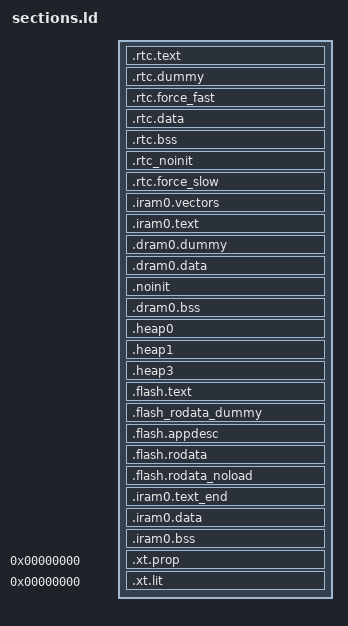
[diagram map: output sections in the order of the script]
/*
 * ESP32-S3 Linker Script Output Sections
 *
 * This Source Code Form is subject to the terms of the Mozilla Public License, v. 2.0.
 * If a copy of the MPL was not distributed with this file, you can obtain one at
 * https://mozilla.org/MPL/2.0/.
 *
 * Copyright 2026, Roku, Inc.  All rights reserved.
 */

/* This file places compiler output into the memory blocks that memory.ld
   describes.  It follows the esp32 script beside it closely; the differences all
   come from two properties of the part, plus one property of LT.

   The D/IRAM overlap.  SRAM1 answers on both buses, so a byte spent on
   .iram0.text is a byte no longer available to .dram0.data.  .dram0.dummy below
   is what keeps the two from being handed out twice: it is a NOLOAD section at
   the head of dram_app0_seg that grows to exactly cover whatever IRAM was used.
   The esp32 needs nothing of the kind.

   Static data and heap0 share a segment.  On the esp32 the ROM and BT carve-outs
   force .data and .bss into dram_app1_seg with heap0 stranded in a separate hole
   below them.  Here there is no hole: .data, .noinit and .bss go at the bottom of
   dram_app0_seg and heap0 takes whatever is left above them, which is the natural
   arrangement and the one IDF uses.

   Archive placement rules name only archives LT actually links.  The esp32
   script was generated by IDF's build system and carries placement rules for
   forty-odd IDF component archives - libfreertos.a, libhal.a, libheap.a and so
   on - that an LT link never sees; they match nothing and are harmless, but
   there is no reason to reproduce them here.  What LT does link is its own
   libraries plus the prebuilt Espressif blobs listed in
   Esp32_MasterFirmwareImage.mk, and those are the ones named below.  Note that
   the esp32s3 set differs from the esp32 set: there is no librtc.a, because
   esp32s3 RTC support lives in ROM, and there is a libbtbb.a, which on the esp32
   is in ROM.
*/

/* Start of SRAM1 on the instruction bus.  .dram0.dummy needs this to work out
   how much of the D/IRAM overlap the IRAM sections consumed. */
_diram_i_start = 0x40378000;

/*  Default entry point:  */
ENTRY(call_start_cpu0);

SECTIONS
{
  /* RTC fast memory holds RTC wake stub code,
     including from any source file named rtc_wake_stub*.c
  */
  .rtc.text :
  {
    . = ALIGN(4);

    *(.rtc.literal .rtc.text .rtc.text.*)

    *rtc_wake_stub*.*(.literal .text .literal.* .text.*)
    _rtc_text_end = ABSOLUTE(.);
  } > rtc_iram_seg

  /*
    This section is required to skip rtc.text area because rtc_iram_seg and
    rtc_data_seg are reflect the same address space on different buses.
  */
  .rtc.dummy :
  {
    _rtc_dummy_start = ABSOLUTE(.);
    _rtc_fast_start = ABSOLUTE(.);
    . = SIZEOF(.rtc.text);
    _rtc_dummy_end = ABSOLUTE(.);
  } > rtc_data_seg

  /* This section located in RTC FAST Memory area.
     It holds data marked with RTC_FAST_ATTR attribute.
     See the file "esp_attr.h" for more information.
  */
  .rtc.force_fast :
  {
    . = ALIGN(4);
    _rtc_force_fast_start = ABSOLUTE(.);

    _coredump_rtc_fast_start = ABSOLUTE(.);
    *(.rtc.fast.coredump .rtc.fast.coredump.*)
    _coredump_rtc_fast_end = ABSOLUTE(.);

    *(.rtc.force_fast .rtc.force_fast.*)
    . = ALIGN(4) ;

    _rtc_force_fast_end = ABSOLUTE(.);
  } > rtc_data_seg

  /* RTC data section holds RTC wake stub
     data/rodata, including from any source file
     named rtc_wake_stub*.c and the data marked with
     RTC_DATA_ATTR, RTC_RODATA_ATTR attributes.
  */
  .rtc.data :
  {
    _rtc_data_start = ABSOLUTE(.);

    _coredump_rtc_start = ABSOLUTE(.);
    *(.rtc.coredump .rtc.coredump.*)
    _coredump_rtc_end = ABSOLUTE(.);
    *(.rtc.data .rtc.data.*)
    *(.rtc.rodata .rtc.rodata.*)

    *rtc_wake_stub*.*(.data .rodata .data.* .rodata.* .bss .bss.*)
    _rtc_data_end = ABSOLUTE(.);

  } > rtc_data_location

  /* RTC bss, from any source file named rtc_wake_stub*.c */
  .rtc.bss (NOLOAD) :
  {
    _rtc_bss_start = ABSOLUTE(.);
    *rtc_wake_stub*.*(.bss .bss.*)
    *rtc_wake_stub*.*(COMMON)

    *(.rtc.bss)

    _rtc_bss_end = ABSOLUTE(.);
  } > rtc_data_location

  /* This section holds data that should not be initialized at power up
     and will be retained during deep sleep.
     User data marked with RTC_NOINIT_ATTR will be placed
     into this section. See the file "esp_attr.h" for more information.
  */
  .rtc_noinit (NOLOAD):
  {
    . = ALIGN(4);
    _rtc_noinit_start = ABSOLUTE(.);
    *(.rtc_noinit .rtc_noinit.*)
    . = ALIGN(4) ;
    _rtc_noinit_end = ABSOLUTE(.);
  } > rtc_data_location

  /* This section located in RTC SLOW Memory area.
     It holds data marked with RTC_SLOW_ATTR attribute.
     See the file "esp_attr.h" for more information.
  */
  .rtc.force_slow :
  {
    . = ALIGN(4);
    _rtc_force_slow_start = ABSOLUTE(.);
    *(.rtc.force_slow .rtc.force_slow.*)
    . = ALIGN(4) ;
    _rtc_force_slow_end = ABSOLUTE(.);
  } > rtc_slow_seg

  /* Get size of rtc slow data based on rtc_data_location alias */
  _rtc_slow_length = (ORIGIN(rtc_slow_seg) == ORIGIN(rtc_data_location))
                        ? (_rtc_force_slow_end - _rtc_data_start)
                        : (_rtc_force_slow_end - _rtc_force_slow_start);

  _rtc_fast_length = (ORIGIN(rtc_slow_seg) == ORIGIN(rtc_data_location))
                        ? (_rtc_force_fast_end - _rtc_fast_start)
                        : (_rtc_noinit_end - _rtc_fast_start);

  ASSERT((_rtc_slow_length <= LENGTH(rtc_slow_seg)),
          "RTC_SLOW segment data does not fit.")

  ASSERT((_rtc_fast_length <= LENGTH(rtc_data_seg)),
          "RTC_FAST segment data does not fit.")

  /* Send .iram0 code to iram */
  .iram0.vectors :
  {
    _iram_start = ABSOLUTE(.);
    /* Vectors go to IRAM */
    _vector_table = ABSOLUTE(.);
    . = 0x0;
    KEEP(*(.WindowVectors.text));
    . = 0x180;
    KEEP(*(.Level2InterruptVector.text));
    . = 0x1c0;
    KEEP(*(.Level3InterruptVector.text));
    . = 0x200;
    KEEP(*(.Level4InterruptVector.text));
    . = 0x240;
    KEEP(*(.Level5InterruptVector.text));
    . = 0x280;
    KEEP(*(.DebugExceptionVector.text));
    . = 0x2c0;
    KEEP(*(.NMIExceptionVector.text));
    . = 0x300;
    KEEP(*(.KernelExceptionVector.text));
    . = 0x340;
    KEEP(*(.UserExceptionVector.text));
    . = 0x3C0;
    KEEP(*(.DoubleExceptionVector.text));
    . = 0x400;
    _invalid_pc_placeholder = ABSOLUTE(.);
    *(.*Vector.literal)

    *(.UserEnter.literal);
    *(.UserEnter.text);
    . = ALIGN (16);
    *(.entry.text)
    *(.init.literal)
    *(.init)

    _init_end = ABSOLUTE(.);
  } > iram0_0_seg

  .iram0.text :
  {
    /* Code marked as running out of IRAM */
    _iram_text_start = ABSOLUTE(.);

    /* The .iram1 catch-all is what places IRAM-resident code out of the
       prebuilt blobs, libbtbb.a among them. */
    *(.iram1 .iram1.*)

    *libnet80211.a:(.wifi0iram .wifi0iram.*)
    *libnet80211.a:(.wifirxiram .wifirxiram.*)
    *libnet80211.a:(.wifislprxiram .wifislprxiram.*)
    *libpp.a:(.wifi0iram .wifi0iram.*)
    *libpp.a:(.wifiorslpiram .wifiorslpiram.*)
    *libpp.a:(.wifirxiram .wifirxiram.*)
    *libpp.a:(.wifislprxiram .wifislprxiram.*)
    *libgcc.a:lib2funcs.*(.literal .literal.* .text .text.*)

  } > iram0_0_seg

  /**
   * This section keeps the IRAM sections above from being handed out a second
   * time as DRAM.  SRAM1 is one block of memory seen on two buses, so whatever
   * .iram0.* consumed between _diram_i_start and _iram_end has to be skipped
   * here before any data section is placed.  MAX(...,0) covers the case where
   * nothing landed in IRAM at all.
   *
   * _iram_end is defined further down, in .iram0.bss.  Referring to it here is
   * deliberate and is what IDF does; ld resolves the forward reference on a
   * later relaxation pass.
   *
   * The expression is not spelled the way IDF spells it, though.  IDF writes
   *
   *   . = ORIGIN(dram0_0_seg) + MAX(_iram_end - _diram_i_start, 0);
   *
   * and that form cannot be used here.  On the first pass _iram_end is still
   * zero, so the subtraction underflows, and ld's MAX compares as bfd_vma -
   * unsigned - so it hands back the underflowed value rather than clamping it
   * to 0.  Every later section in this segment then starts from a negative dot.
   * IDF gets away with it because nothing in dram0_0_seg pins the location
   * counter to an absolute value, so the bad first pass is simply discarded.
   * Here .heap0 and .heap1 do pin it, and a first pass that runs backwards is a
   * fatal "cannot move location counter backwards" before the second pass ever
   * happens.  Taking the MAX of the two addresses first keeps both operands
   * positive and makes the unsigned comparison do what was meant.
   */
  .dram0.dummy (NOLOAD):
  {
    . = ORIGIN(dram_app0_seg) + MAX(_iram_end, _diram_i_start) - _diram_i_start;
  } > dram_app0_seg

  .dram0.data :
  {
    _data_start = ABSOLUTE(.);
    *(.gnu.linkonce.d.*)
    *(.data1)
    *(.sdata)
    *(.sdata.*)
    *(.gnu.linkonce.s.*)
    *(.sdata2)
    *(.sdata2.*)
    *(.gnu.linkonce.s2.*)
    *(.jcr)

    _esp_system_init_fn_array_start = ABSOLUTE(.);
    KEEP (*(SORT(.esp_system_init_fn) SORT(.esp_system_init_fn.*)))
    _esp_system_init_fn_array_end = ABSOLUTE(.);

    *(EXCLUDE_FILE(*libbtdm_app.a *libbtbb.a) .data EXCLUDE_FILE(*libbtdm_app.a *libbtbb.a) .data.*)
    *(.dram1 .dram1.*)
    _coredump_dram_start = ABSOLUTE(.);
    *(.dram1.coredump .dram1.coredump.*)
    _coredump_dram_end = ABSOLUTE(.);
    _btdm_data_start = ABSOLUTE(.);
    *libbtdm_app.a:(.data .data.*)
    *libbtbb.a:(.data .data.*)
    . = ALIGN(4);
    _btdm_data_end = ABSOLUTE(.);
    *libphy.a:(.rodata .rodata.*)

    _data_end = ABSOLUTE(.);
    . = ALIGN(4);
  } > dram_app0_seg

  /*This section holds data that should not be initialized at power up.
    The section located in Internal SRAM memory region. The macro _NOINIT
    can be used as attribute to place data into this section.
    See the esp_attr.h file for more information.
  */
  .noinit (NOLOAD):
  {
    . = ALIGN(4);
    _noinit_start = ABSOLUTE(.);
    *(.noinit .noinit.*)
    . = ALIGN(4) ;
    _noinit_end = ABSOLUTE(.);
  } > dram_app0_seg

  /* Shared RAM */
  .dram0.bss (NOLOAD) :
  {
    . = ALIGN (8);
    _bss_start = ABSOLUTE(.);

    *(.bss .bss.*)
    *(.dynbss .dynsbss .gnu.linkonce.b .gnu.linkonce.b.* .gnu.linkonce.sb .gnu.linkonce.sb.* .gnu.linkonce.sb2 .gnu.linkonce.sb2.* .sbss .sbss.* .sbss2 .sbss2.* .scommon .share.mem)
    *(COMMON)
    _btdm_bss_start = ABSOLUTE(.);
    *libbtdm_app.a:(.bss .bss.* COMMON)
    *libbtbb.a:(.bss .bss.* COMMON)
    . = ALIGN(4);
    _btdm_bss_end = ABSOLUTE(.);

    . = ALIGN (8);
    _bss_end = ABSOLUTE(.);
  } > dram_app0_seg

  /* Everything left over in dram_app0_seg once the IRAM overlap and the static
     data are accounted for.  This is the main heap. */
  .heap0 (NOLOAD) :
  {
     _heap0_start = ABSOLUTE(.);
     . = ORIGIN(dram_app0_seg) + LENGTH(dram_app0_seg);
     _heap0_end = ABSOLUTE(.);
  } > dram_app0_seg

  /* The second stage bootloader's own footprint, dead once it hands over. */
  .heap1 (NOLOAD) :
  {
     _heap1_start = ABSOLUTE(.);
     . += LENGTH(dram_app1_seg);
     _heap1_end = ABSOLUTE(.);
  } > dram_app1_seg

  /* SRAM2 below the data cache.  DRAM only - no instruction bus alias, so
     nothing here needs a .dram0.dummy style skip. */
  .heap3 (NOLOAD) :
  {
     _heap3_start = ABSOLUTE(.);
     . += LENGTH(dram_app3_seg);
     _heap3_end = ABSOLUTE(.);
  } > dram_app3_seg

  /* Note the absence of a .heap2.  On the esp32 heap2 is the small hole between
     two ROM data islands in the middle of DRAM; the esp32s3 has no such island,
     so the number is simply retired here rather than reused for something else.
     Esp32_LTCoreBSP.c keeps the esp32 numbering intact for the same reason -
     LTMemoryRegion values are positional and are bound to names in
     LTDeviceConfig.json. */

  /* Note also the absence of .ext_ram_noinit and .ext_ram.bss.  PSRAM on the
     esp32s3 shares the 0x3C000000 window with flash rodata and is mapped at
     runtime above whatever drom actually uses, so there is no fixed address for
     the linker to place anything at.  Esp32_PSRAM.c registers it as a heap
     region instead. */

  /* Flash text is laid out before flash rodata, and must stay that way.  The
     esp32s3 has one 512 entry cache MMU table shared by the instruction and the
     data bus, and an entry is selected by the virtual address alone:
     (vaddr & 0x1FFFFFF) >> 16.  Because irom starts at 0x42000000 and drom at
     0x3C000000, both windows index that table from entry 0, so a naive layout has
     the two segments fighting over the same entries and whichever the bootloader
     maps second wins - every rodata read then returns instruction bytes.

     The separation is achieved here, in the layout, and nowhere else: .flash.text
     is placed first so that the .flash_rodata_dummy gap below can reserve as many
     virtual pages as it occupies.  irom therefore keeps the low entries and drom
     starts above it.  Esp32_LTChipStart.c tells the cache the resulting split with
     Cache_Set_IDROM_MMU_Size(), which takes sizes rather than addresses and so
     assumes exactly this order. */
  .flash.text :
  {
    _stext = .;
    _text_start = ABSOLUTE(.);

    *(EXCLUDE_FILE(*libgcc.a:lib2funcs.*) .literal EXCLUDE_FILE(*libgcc.a:lib2funcs.*) .literal.* EXCLUDE_FILE(*libgcc.a:lib2funcs.*) .text EXCLUDE_FILE(*libgcc.a:lib2funcs.*) .text.*)
    *(EXCLUDE_FILE(*libnet80211.a *libpp.a) .wifi0iram EXCLUDE_FILE(*libnet80211.a *libpp.a) .wifi0iram.*)
    *(EXCLUDE_FILE(*libpp.a) .wifiorslpiram EXCLUDE_FILE(*libpp.a) .wifiorslpiram.*)
    *(EXCLUDE_FILE(*libnet80211.a *libpp.a) .wifirxiram EXCLUDE_FILE(*libnet80211.a *libpp.a) .wifirxiram.*)
    *(.wifislpiram .wifislpiram.*)
    *(EXCLUDE_FILE(*libnet80211.a *libpp.a) .wifislprxiram EXCLUDE_FILE(*libnet80211.a *libpp.a) .wifislprxiram.*)

    *(.stub .gnu.warning .gnu.linkonce.literal.* .gnu.linkonce.t.*.literal .gnu.linkonce.t.*)
    *(.irom0.text) /* catch stray ICACHE_RODATA_ATTR */
    *(.fini.literal)
    *(.fini)
    *(.gnu.version)

    /** CPU will try to prefetch up to 16 bytes of
      * of instructions. This means that any configuration (e.g. MMU, PMS) must allow
      * safe access to up to 16 bytes after the last real instruction, add
      * dummy bytes to ensure this
      */
    . += _esp_flash_mmap_prefetch_pad_size;

    _text_end = ABSOLUTE(.);
    _etext = .;

    /* Similar to _iram_start, this symbol goes here so it is
       resolved by addr2line in preference to the first symbol in
       the flash.text segment.
    */
    _flash_cache_start = ABSOLUTE(0);
  } >default_code_seg

  /* Occupies the drom virtual pages that irom has already claimed in the shared
     MMU table, so that the rodata below lands on pages of its own.  NOLOAD, so it
     costs virtual address space only and nothing is written to flash for it. */
  .flash_rodata_dummy (NOLOAD) :
  {
    _flash_rodata_dummy_start = .;

    /* Start at the same alignment constraint as .flash.text */
    . = ALIGN(ALIGNOF(.flash.text));

    /* Create an empty gap as big as .flash.text */
    . = . + SIZEOF(.flash.text);

    /* Round up to the next MMU page, leaving the 0x20 bytes the image loader
       needs for the segment's mapping header. */
    . = ALIGN(0x10000) + 0x20;

    _rodata_reserved_start = .;
  } > default_rodata_seg

  .flash.appdesc : ALIGN(0x10)
  {
    _rodata_start = ABSOLUTE(.);

    *(.rodata_desc .rodata_desc.*)               /* Should be the first.  App version info.        DO NOT PUT ANYTHING BEFORE IT! */
    *(.rodata_custom_desc .rodata_custom_desc.*) /* Should be the second. Custom app version info. DO NOT PUT ANYTHING BEFORE IT! */

    /* Create an empty gap within this section. Thanks to this, the end of this
     * section will match .flash.rodata's begin address. Thus, both sections
     * will be merged when creating the final bin image. */
    . = ALIGN(ALIGNOF(.flash.rodata));
  } >default_rodata_seg

  .flash.rodata : ALIGN(0x10)
  {
    _flash_rodata_start = ABSOLUTE(.);

    *(EXCLUDE_FILE(*libphy.a) .rodata EXCLUDE_FILE(*libphy.a) .rodata.*)
    *(.rodata_wlog_error .rodata_wlog_error.*)
    *(.rodata_wlog_info .rodata_wlog_info.*)
    *(.rodata_wlog_warning .rodata_wlog_warning.*)

    *(.irom1.text) /* catch stray ICACHE_RODATA_ATTR */
    *(.gnu.linkonce.r.*)
    *(.rodata1)
    __XT_EXCEPTION_TABLE_ = ABSOLUTE(.);
    *(.xt_except_table)
    *(.gcc_except_table .gcc_except_table.*)
    *(.gnu.linkonce.e.*)
    *(.gnu.version_r)
    . = (. + 3) & ~ 3;
    __eh_frame = ABSOLUTE(.);
    KEEP(*(.eh_frame))
    . = (. + 7) & ~ 3;
    /*  C++ constructor and destructor tables

        Make a point of not including anything from crtbegin.o or crtend.o, as IDF doesn't use toolchain crt
      */
    __init_array_start = ABSOLUTE(.);
    KEEP (*(EXCLUDE_FILE (*crtend.* *crtbegin.*) .ctors SORT(.ctors.*)))
    __init_array_end = ABSOLUTE(.);

    KEEP (*crtbegin.*(.dtors))
    KEEP (*(EXCLUDE_FILE (*crtend.*) .dtors))
    KEEP (*(SORT(.dtors.*)))
    KEEP (*(.dtors))
    /*  C++ exception handlers table:  */
    __XT_EXCEPTION_DESCS_ = ABSOLUTE(.);
    *(.xt_except_desc)
    *(.gnu.linkonce.h.*)
    __XT_EXCEPTION_DESCS_END__ = ABSOLUTE(.);
    *(.xt_except_desc_end)
    *(.dynamic)
    *(.gnu.version_d)
    /* Addresses of memory regions reserved via
       SOC_RESERVE_MEMORY_REGION() */
    soc_reserved_memory_region_start = ABSOLUTE(.);
    KEEP (*(.reserved_memory_address))
    soc_reserved_memory_region_end = ABSOLUTE(.);
    _rodata_end = ABSOLUTE(.);
    /* Literals are also RO data. */
    _lit4_start = ABSOLUTE(.);
    *(*.lit4)
    *(.lit4.*)
    *(.gnu.linkonce.lit4.*)
    _lit4_end = ABSOLUTE(.);
    . = ALIGN(4);
    _thread_local_start = ABSOLUTE(.);
    *(.tdata)
    *(.tdata.*)
    *(.tbss)
    *(.tbss.*)
    _thread_local_end = ABSOLUTE(.);
    . = ALIGN(4);
    *(.eram.rodata.audsamples)
  } >default_rodata_seg

  _flash_rodata_align = ALIGNOF(.flash.rodata);

  .flash.rodata_noload (NOLOAD) :
  {
    /* Marks the end of the rodata that actually occupies flash MMU pages.  The
       noload rodata below it costs no virtual address space, so it is excluded
       deliberately.  Esp32_PSRAM.c reads this to work out how far up the DRAM0
       cache bus the flash mapping reaches, and therefore where PSRAM may be
       mapped without colliding with it. */
    _rodata_reserved_end = ABSOLUTE(.);

    . = ALIGN (4);
    *(.rodata_wlog_debug .rodata_wlog_debug.*)
    *(.rodata_wlog_verbose .rodata_wlog_verbose.*)
  } > default_rodata_seg

  /* Marks the end of IRAM code segment */
  .iram0.text_end (NOLOAD) :
  {
    /* ESP32-S3 memprot requires 16B padding for possible CPU prefetch and 256B alignment for PMS split lines */
    . += _esp_memprot_prefetch_pad_size;
    . = ALIGN(_esp_memprot_align_size);
    . = ALIGN (4);
    _iram_text_end = ABSOLUTE(.);
  } > iram0_0_seg

  .iram0.data :
  {
    . = ALIGN(4);
    _iram_data_start = ABSOLUTE(.);

    *(.iram.data .iram.data.*)
    _coredump_iram_start = ABSOLUTE(.);
    *(.iram.data.coredump .iram.data.coredump.*)
    _coredump_iram_end = ABSOLUTE(.);

    _iram_data_end = ABSOLUTE(.);
  } > iram0_0_seg

  .iram0.bss (NOLOAD) :
  {
    . = ALIGN(4);
    _iram_bss_start = ABSOLUTE(.);

    *(.iram.bss .iram.bss.*)

    _iram_bss_end = ABSOLUTE(.);
    . = ALIGN(4);
    _iram_end = ABSOLUTE(.);
   } > iram0_0_seg

  /** This section will be used by the debugger and disassembler to get more information
    * about raw data present in the code.
    */
  .xt.prop 0 :
  {
    KEEP (*(.xt.prop .gnu.linkonce.prop.*))
  }

  .xt.lit 0 :
  {
    KEEP (*(.xt.lit .gnu.linkonce.p.*))
  }
}

ASSERT(((_iram_end - ORIGIN(iram0_0_seg)) <= LENGTH(iram0_0_seg)),
          "IRAM0 segment data does not fit.")

/* dram_app0_seg carries the IRAM overlap, the static data and heap0, so this is
   the check that the three together still fit.  If it fires, either the image
   grew or the segment boundaries in memory.ld moved. */
ASSERT(((_heap0_end - ORIGIN(dram_app0_seg)) <= LENGTH(dram_app0_seg)),
          "LT heap0 segment does not fit.")

/* Static data must not run past the start of heap0.  The ASSERT above would
   catch that too, but only after the fact and with a less helpful message. */
ASSERT((_bss_end <= _heap0_start),
          "Static data overruns the start of LT heap0.")

ASSERT(((_heap1_end - ORIGIN(dram_app1_seg)) <= LENGTH(dram_app1_seg)),
          "LT heap1 segment does not fit.")

ASSERT(((_heap3_end - ORIGIN(dram_app3_seg)) <= LENGTH(dram_app3_seg)),
          "LT heap3 segment does not fit.")

/*******************************************************************************
 *  LOG
 *******************************************************************************
 *  28-Jul-26   claudius    created
 *  03-Aug-26   claudius    .flash_rodata_dummy gap: irom and drom share one MMU table
 */
